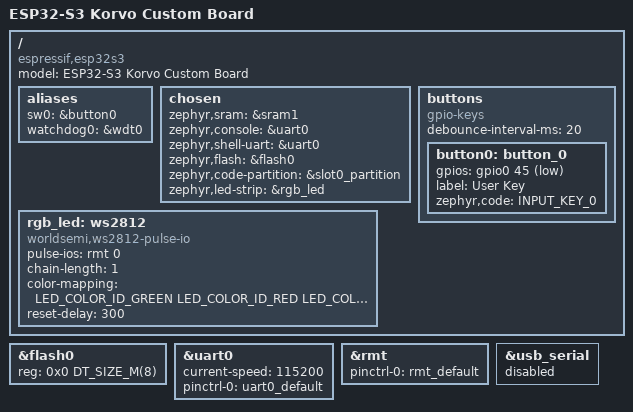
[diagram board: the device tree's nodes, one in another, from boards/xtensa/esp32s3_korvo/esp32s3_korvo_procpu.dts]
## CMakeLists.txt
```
cmake_minimum_required(VERSION 3.30.0)

find_package(Zephyr REQUIRED HINTS $ENV{ZEPHYR_BASE})
project(input_btn)

target_sources(app PRIVATE src/main.c)
```

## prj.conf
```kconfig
# SPDX-License-Identifier: Apache-2.0

CONFIG_GPIO=y

# 按键：input 核心 + gpio-keys 驱动
CONFIG_INPUT=y
CONFIG_INPUT_GPIO_KEYS=y

# 板载 WS2812（IO48，走 RMT）：按键控制它的亮/灭
CONFIG_LED_STRIP=y
CONFIG_WS2812_STRIP_PULSE_IO=y
```

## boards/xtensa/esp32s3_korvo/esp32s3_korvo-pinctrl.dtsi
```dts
/*
 * SPDX-License-Identifier: Apache-2.0
 *
 * 引脚复用：把芯片的物理引脚映射到外设功能，并给出电气特性。
 * - uart0：控制台（IO43 / IO44）
 * - rmt  ：驱动板载 WS2812 的数据脚（IO48）
 */

#include <zephyr/dt-bindings/pinctrl/esp32s3-pinctrl.h>

&pinctrl {
	uart0_default: uart0_default {
		group1 {
			pinmux = <UART0_TX_GPIO43>;
			output-high;
		};

		group2 {
			pinmux = <UART0_RX_GPIO44>;
			bias-pull-up;
		};
	};

	rmt_default: rmt_default {
		group1 {
			pinmux = <RMT_OUT0_GPIO48>;
		};
	};
};
```

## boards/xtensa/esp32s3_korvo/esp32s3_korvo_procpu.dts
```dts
/*
 * SPDX-License-Identifier: Apache-2.0
 *
 * 板级资源（按我们手上的板子）：
 *   - 用户按键 KEY : GPIO45，按下接地（INPUT_KEY_0）
 *   - 板载 RGB    : WS2812 一颗，数据脚 GPIO48，走 RMT
 *   - 控制台       : uart0（IO43 TX / IO44 RX，USB-Serial-JTAG）
 */

/dts-v1/;

#include <espressif/esp32s3/esp32s3.dtsi>
#include <espressif/partitions_0x0_amp.dtsi>
#include <zephyr/dt-bindings/led/led.h>
#include <zephyr/dt-bindings/input/input-event-codes.h>
#include "esp32s3_korvo-pinctrl.dtsi"

/ {
	compatible = "espressif,esp32s3";
	model = "ESP32-S3 Korvo Custom Board";

	aliases {
		sw0 = &button0;
		watchdog0 = &wdt0;
	};

	chosen {
		zephyr,sram = &sram1;
		zephyr,console = &uart0;
		zephyr,shell-uart = &uart0;
		zephyr,flash = &flash0;
		zephyr,code-partition = &slot0_partition;
		zephyr,led-strip = &rgb_led;
	};

	/* 板载 WS2812 一颗：RMT 通道 0，物理顺序 GRB */
	rgb_led: ws2812 {
		compatible = "worldsemi,ws2812-pulse-io";
		pulse-ios = <&rmt 0>;
		chain-length = <1>;
		color-mapping = <LED_COLOR_ID_GREEN
				 LED_COLOR_ID_RED
				 LED_COLOR_ID_BLUE>;
		reset-delay = <300>;
	};

	/* 用户按键 KEY：IO45，按下接地；第四课起加 20ms 统一消抖 */
	buttons {
		compatible = "gpio-keys";
		debounce-interval-ms = <20>;

		button0: button_0 {
			gpios = <&gpio0 45 (GPIO_PULL_UP | GPIO_ACTIVE_LOW)>;
			label = "User Key";
			zephyr,code = <INPUT_KEY_0>;
		};
	};
};

&flash0 {
	reg = <0x0 DT_SIZE_M(8)>;
	ranges = <0x0 0x0 DT_SIZE_M(8)>;
};

&uart0 {
	current-speed = <115200>;
	pinctrl-0 = <&uart0_default>;
	pinctrl-names = "default";
	status = "okay";
};

&rmt {
	pinctrl-0 = <&rmt_default>;
	pinctrl-names = "default";
	status = "okay";
};

&usb_serial {
	status = "disabled";
};
```

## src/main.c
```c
/*
 * SPDX-License-Identifier: Apache-2.0
 *
 * 第四课：按键控制板载 RGB。
 *
 * - 键码来自 dts（buttons/button0 -> INPUT_KEY_0），代码只认键码，不认引脚（KEY 在 IO45）
 * - 灯来自 dts 的 chosen（zephyr,led-strip）-> 板载 WS2812，数据脚 IO48
 * - 为什么不用 gpio-leds：WS2812 是单线时序器件，必须走 led_strip 驱动
 */

#include <zephyr/kernel.h>
#include <zephyr/drivers/led_strip.h>
#include <zephyr/input/input.h>

#define STRIP_NODE DT_CHOSEN(zephyr_led_strip)
static const struct device *strip = DEVICE_DT_GET(STRIP_NODE);

static bool led_on;

static void apply_led(void)
{
	struct led_rgb px = led_on ? (struct led_rgb){ .r = 0x20, .g = 0x20, .b = 0x20 }
				   : (struct led_rgb){ .r = 0x00, .g = 0x00, .b = 0x00 };

	led_strip_update_rgb(strip, &px, 1);
}

static void input_call_back(struct input_event *event, void *user_data)
{
	ARG_UNUSED(user_data);

	/* 只处理按键类事件 */
	if (event->type != INPUT_EV_KEY) {
		return;
	}

	/* 默认双边沿：value=1 是按下，0 是松开。只响应按下 */
	if ((event->code == INPUT_KEY_0) && (event->value == 1)) {
		led_on = !led_on;
		apply_led();
	}
}

INPUT_CALLBACK_DEFINE(NULL, input_call_back, NULL);

int main(void)
{
	if (!device_is_ready(strip)) {
		return -1;
	}

	apply_led();

	while (1) {
		k_msleep(1000);
	}

	return 0;
}
```
